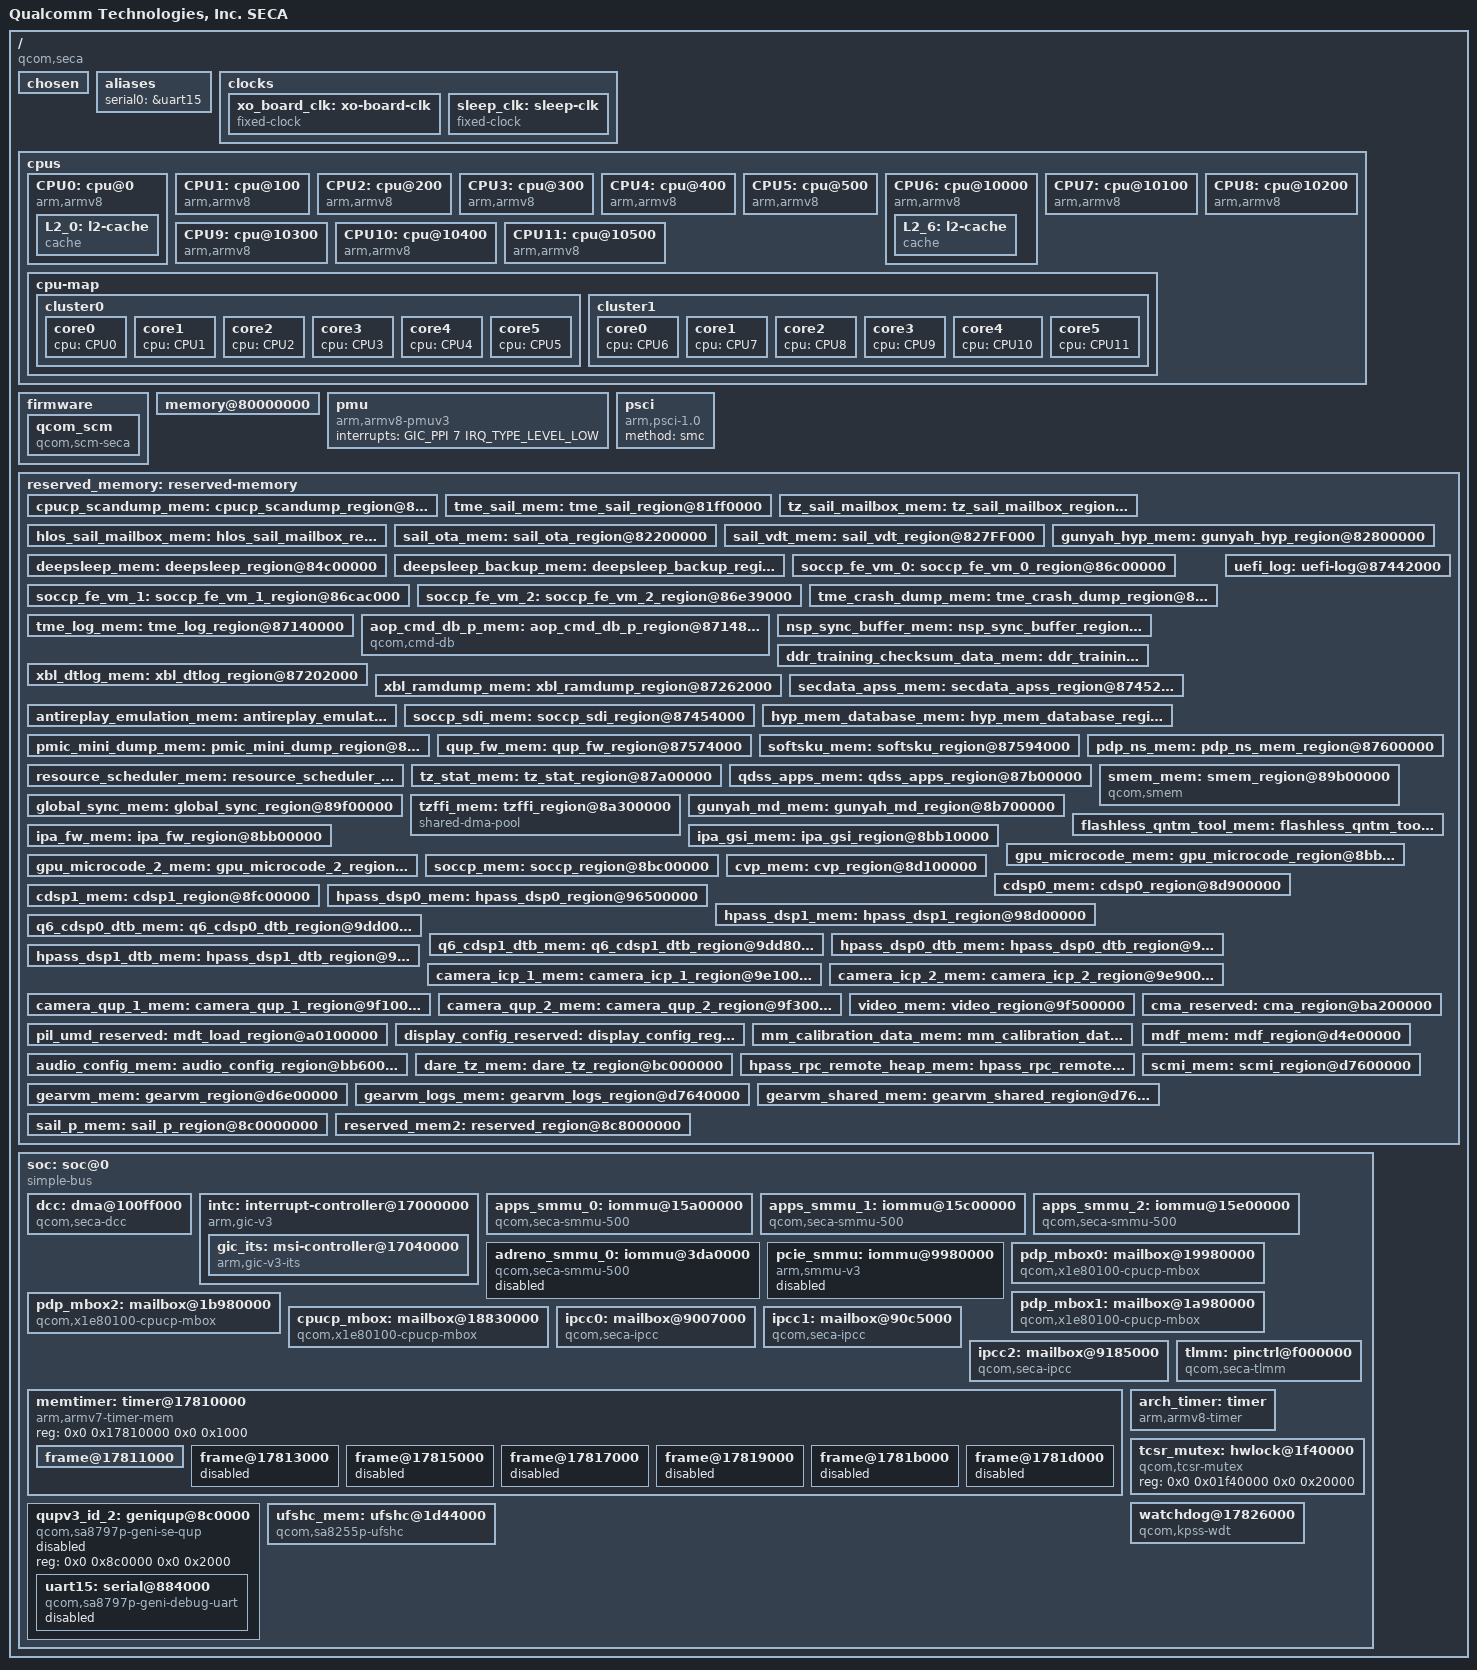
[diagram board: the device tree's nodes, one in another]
// SPDX-License-Identifier: BSD-3-Clause
/*
 * Copyright (c) Qualcomm Technologies, Inc. and/or its subsidiaries.
 */

#include <dt-bindings/interrupt-controller/arm-gic.h>
#include <dt-bindings/gpio/gpio.h>

/ {
	model = "Qualcomm Technologies, Inc. SECA";
	compatible = "qcom,seca";
	qcom,msm-id = <742 0x10000>;

	interrupt-parent = <&intc>;

	#address-cells = <2>;
	#size-cells = <2>;

	chosen { };

	aliases {
		serial0 = &uart15;
	};

	clocks {
		xo_board_clk: xo-board-clk {
			compatible = "fixed-clock";
			#clock-cells = <0>;
		};

		sleep_clk: sleep-clk {
			compatible = "fixed-clock";
			#clock-cells = <0>;
		};
	};

	cpus {
		#address-cells = <2>;
		#size-cells = <0>;

		CPU0: cpu@0 {
			device_type = "cpu";
			compatible = "arm,armv8";
			reg = <0x0 0x0>;
			enable-method = "psci";
			next-level-cache = <&L2_0>;
			L2_0: l2-cache {
				compatible = "cache";
				cache-level = <2>;
				cache-unified;
			};
		};

		CPU1: cpu@100 {
			device_type = "cpu";
			compatible = "arm,armv8";
			reg = <0x0 0x100>;
			enable-method = "psci";
			next-level-cache = <&L2_0>;
		};

		CPU2: cpu@200 {
			device_type = "cpu";
			compatible = "arm,armv8";
			reg = <0x0 0x200>;
			enable-method = "psci";
			next-level-cache = <&L2_0>;
		};

		CPU3: cpu@300 {
			device_type = "cpu";
			compatible = "arm,armv8";
			reg = <0x0 0x300>;
			enable-method = "psci";
			next-level-cache = <&L2_0>;
		};

		CPU4: cpu@400 {
			device_type = "cpu";
			compatible = "arm,armv8";
			reg = <0x0 0x400>;
			enable-method = "psci";
			next-level-cache = <&L2_0>;
		};

		CPU5: cpu@500 {
			device_type = "cpu";
			compatible = "arm,armv8";
			reg = <0x0 0x500>;
			enable-method = "psci";
			next-level-cache = <&L2_0>;
		};

		CPU6: cpu@10000 {
			device_type = "cpu";
			compatible = "arm,armv8";
			reg = <0x0 0x10000>;
			enable-method = "psci";
			next-level-cache = <&L2_6>;
			L2_6: l2-cache {
				compatible = "cache";
				cache-level = <2>;
				cache-unified;
			};
		};

		CPU7: cpu@10100 {
			device_type = "cpu";
			compatible = "arm,armv8";
			reg = <0x0 0x10100>;
			enable-method = "psci";
			next-level-cache = <&L2_6>;
		};

		CPU8: cpu@10200 {
			device_type = "cpu";
			compatible = "arm,armv8";
			reg = <0x0 0x10200>;
			enable-method = "psci";
			next-level-cache = <&L2_6>;
		};

		CPU9: cpu@10300 {
			device_type = "cpu";
			compatible = "arm,armv8";
			reg = <0x0 0x10300>;
			enable-method = "psci";
			next-level-cache = <&L2_6>;
		};

		CPU10: cpu@10400 {
			device_type = "cpu";
			compatible = "arm,armv8";
			reg = <0x0 0x10400>;
			enable-method = "psci";
			next-level-cache = <&L2_6>;
		};

		CPU11: cpu@10500 {
			device_type = "cpu";
			compatible = "arm,armv8";
			reg = <0x0 0x10500>;
			enable-method = "psci";
			next-level-cache = <&L2_6>;
		};

		cpu-map {
			cluster0 {
				core0 {
					cpu = <&CPU0>;
				};

				core1 {
					cpu = <&CPU1>;
				};

				core2 {
					cpu = <&CPU2>;
				};

				core3 {
					cpu = <&CPU3>;
				};

				core4 {
					cpu = <&CPU4>;
				};

				core5 {
					cpu = <&CPU5>;
				};
			};

			cluster1 {
				core0 {
					cpu = <&CPU6>;
				};

				core1 {
					cpu = <&CPU7>;
				};

				core2 {
					cpu = <&CPU8>;
				};

				core3 {
					cpu = <&CPU9>;
				};

				core4 {
					cpu = <&CPU10>;
				};

				core5 {
					cpu = <&CPU11>;
				};
			};
		};
	};

	firmware {
		qcom_scm {
			compatible = "qcom,scm-seca", "qcom,scm";
		};
	};

	memory@80000000 {
		ddr_device_type = <0x08>;
		device_type = "memory";
		reg = <0x0 0x80000000 0x0 0x80000000>;
	};

	pmu {
		compatible = "arm,armv8-pmuv3";
		interrupts = <GIC_PPI 7 IRQ_TYPE_LEVEL_LOW>;
	};

	psci {
		compatible = "arm,psci-1.0";
		method = "smc";
	};

	reserved_memory: reserved-memory {
		#address-cells = <2>;
		#size-cells = <2>;
		ranges;

		cpucp_scandump_mem: cpucp_scandump_region@80000000 {
			no-map;
			reg = <0x0 0x80000000 0x0 0x800000>;
		};

		tme_sail_mem: tme_sail_region@81ff0000 {
			no-map;
			reg = <0x0 0x81ff0000 0x0 0x10000>;
		};

		tz_sail_mailbox_mem: tz_sail_mailbox_region@82000000 {
			no-map;
			reg = <0x0 0x82000000 0x0 0x8000>;
		};

		hlos_sail_mailbox_mem: hlos_sail_mailbox_region@82008000 {
			no-map;
			reg = <0x0 0x82008000 0x0 0x1F8000>;
		};

		sail_ota_mem: sail_ota_region@82200000 {
			no-map;
			reg = <0x0 0x82200000 0x0 0x5FF000>;
		};

		sail_vdt_mem: sail_vdt_region@827FF000 {
			no-map;
			reg = <0x0 0x827FF000 0x0 0x1000>;
		};

		gunyah_hyp_mem: gunyah_hyp_region@82800000 {
			no-map;
			reg = <0x0 0x82800000 0x0 0x2400000>;
		};

		deepsleep_mem: deepsleep_region@84c00000 {
			no-map;
			reg = <0x0 0x84c00000 0x0 0x800000>;
		};

		deepsleep_backup_mem: deepsleep_backup_region@86a00000 {
			no-map;
			reg = <0x0 0x86a00000 0x0 0x200000>;
		};

		soccp_fe_vm_0: soccp_fe_vm_0_region@86c00000 {
			no-map;
			reg = <0x0 0x86c00000 0x0 0xac000>;
		};

		soccp_fe_vm_1: soccp_fe_vm_1_region@86cac000 {
			no-map;
			reg = <0x0 0x86cac000 0x0 0x18d000>;
		};

		soccp_fe_vm_2: soccp_fe_vm_2_region@86e39000 {
			no-map;
			reg = <0x0 0x86e39000 0x0 0x1c7000>;
		};

		tme_crash_dump_mem: tme_crash_dump_region@87000000 {
			no-map;
			reg = <0x0 0x87000000 0x0 0xa0000>;
		};

		tme_log_mem: tme_log_region@87140000 {
			no-map;
			reg = <0x0 0x87140000 0x0 0x4000>;
		};

		aop_cmd_db_p_mem: aop_cmd_db_p_region@87148000 {
			compatible = "qcom,cmd-db";
			no-map;
			reg = <0x0 0x87148000 0x0 0x20000>;
		};

		nsp_sync_buffer_mem: nsp_sync_buffer_region@871ff000 {
			no-map;
			reg = <0x0 0x871ff000 0x0 0x1000>;
		};

		ddr_training_checksum_data_mem: ddr_training_checksum_data_region@87200000 {
			no-map;
			reg = <0x0 0x87200000 0x0 0x2000>;
		};

		xbl_dtlog_mem: xbl_dtlog_region@87202000 {
			no-map;
			reg = <0x0 0x87202000 0x0 0x60000>;
		};

		xbl_ramdump_mem: xbl_ramdump_region@87262000 {
			no-map;
			reg = <0x0 0x87262000 0x0 0x1c0000>;
		};

		uefi_log: uefi-log@87442000 {
			reg = <0x0 0x87442000 0x0 0x10000>;
			no-map;
		};

		secdata_apss_mem: secdata_apss_region@87452000 {
			no-map;
			reg = <0x0 0x87452000 0x0 0x1000>;
		};

		antireplay_emulation_mem: antireplay_emulation_region@87453000 {
			no-map;
			reg = <0x0 0x87453000 0x0 0x1000>;
		};

		soccp_sdi_mem: soccp_sdi_region@87454000 {
			no-map;
			reg = <0x0 0x87454000 0x0 0x40000>;
		};

		hyp_mem_database_mem: hyp_mem_database_region@87494000 {
			no-map;
			reg = <0x0 0x87494000 0x0 0x60000>;
		};

		pmic_mini_dump_mem: pmic_mini_dump_region@874f4000 {
			no-map;
			reg = <0x0 0x874f4000 0x0 0x80000>;
		};

		qup_fw_mem: qup_fw_region@87574000 {
			no-map;
			reg = <0x0 0x87574000 0x0 0x20000>;
		};

		softsku_mem: softsku_region@87594000 {
			no-map;
			reg = <0x0 0x87594000 0x0 0x9000>;
		};

		resource_scheduler_mem: resource_scheduler_region@8759d000 {
			no-map;
			reg = <0x0 0x8759d000 0x0 0x20000>;
		};

		pdp_ns_mem: pdp_ns_mem_region@87600000 {
			no-map;
			reg = <0x0 0x87600000 0x0 0x200000>;
		};

		tz_stat_mem: tz_stat_region@87a00000 {
			no-map;
			reg = <0x0 0x87a00000 0x0 0x100000>;
		};

		qdss_apps_mem: qdss_apps_region@87b00000 {
			no-map;
			reg = <0x0 0x87b00000 0x0 0x2000000>;
		};

		smem_mem: smem_region@89b00000 {
			compatible = "qcom,smem";
			no-map;
			reg = <0x0 0x89b00000 0x0 0x400000>;
			hwlocks = <&tcsr_mutex 3>;
		};

		global_sync_mem: global_sync_region@89f00000 {
			no-map;
			reg = <0x0 0x89f00000 0x0 0x400000>;
		};

		tzffi_mem: tzffi_region@8a300000 {
			compatible = "shared-dma-pool";
			reg = <0x0 0x8a300000 0x0 0x1400000>;
			no-map;
		};

		gunyah_md_mem: gunyah_md_region@8b700000 {
			no-map;
			reg = <0x0 0x8b700000 0x0 0x80000>;
		};

		flashless_qntm_tool_mem: flashless_qntm_tool_region@8b780000 {
			no-map;
			reg = <0x0 0x8b780000 0x0 0x182000>;
		};

		ipa_fw_mem: ipa_fw_region@8bb00000 {
			no-map;
			reg = <0x0 0x8bb00000 0x0 0x10000>;
		};

		ipa_gsi_mem: ipa_gsi_region@8bb10000 {
			no-map;
			reg = <0x0 0x8bb10000 0x0 0xa000>;
		};

		gpu_microcode_mem: gpu_microcode_region@8bb1a000 {
			no-map;
			reg = <0x0 0x8bb1a000 0x0 0x2000>;
		};

		gpu_microcode_2_mem: gpu_microcode_2_region@8bb1c000 {
			no-map;
			reg = <0x0 0x8bb1c000 0x0 0x2000>;
		};

		soccp_mem: soccp_region@8bc00000 {
			no-map;
			reg = <0x0 0x8bc00000 0x0 0x300000>;
		};

		cvp_mem: cvp_region@8d100000 {
			no-map;
			reg = <0x0 0x8d100000 0x0 0x800000>;
		};

		cdsp0_mem: cdsp0_region@8d900000 {
			no-map;
			reg = <0x0 0x8d900000 0x0 0x2300000>;
		};

		cdsp1_mem: cdsp1_region@8fc00000 {
			no-map;
			reg = <0x0 0x8fc00000 0x0 0x2300000>;
		};

		hpass_dsp0_mem: hpass_dsp0_region@96500000 {
			no-map;
			reg = <0x0 0x96500000 0x0 0x2800000>;
		};

		hpass_dsp1_mem: hpass_dsp1_region@98d00000 {
			no-map;
			reg = <0x0 0x98d00000 0x0 0x2800000>;
		};

		q6_cdsp0_dtb_mem: q6_cdsp0_dtb_region@9dd00000 {
			no-map;
			reg = <0x0 0x9dd00000 0x0 0x80000>;
		};

		q6_cdsp1_dtb_mem: q6_cdsp1_dtb_region@9dd80000 {
			no-map;
			reg = <0x0 0x9dd80000 0x0 0x80000>;
		};

		hpass_dsp0_dtb_mem: hpass_dsp0_dtb_region@9df00000 {
			no-map;
			reg = <0x0 0x9df00000 0x0 0x80000>;
		};

		hpass_dsp1_dtb_mem: hpass_dsp1_dtb_region@9df80000 {
			no-map;
			reg = <0x0 0x9df80000 0x0 0x80000>;
		};

		camera_icp_1_mem: camera_icp_1_region@9e100000 {
			no-map;
			reg = <0x0 0x9e100000 0x0 0x800000>;
		};

		camera_icp_2_mem: camera_icp_2_region@9e900000 {
			no-map;
			reg = <0x0 0x9e900000 0x0 0x800000>;
		};

		camera_qup_1_mem: camera_qup_1_region@9f100000 {
			no-map;
			reg = <0x0 0x9f100000 0x0 0x200000>;
		};

		camera_qup_2_mem: camera_qup_2_region@9f300000 {
			no-map;
			reg = <0x0 0x9f300000 0x0 0x200000>;
		};

		video_mem: video_region@9f500000 {
			no-map;
			reg = <0x0 0x9f500000 0x0 0xc00000>;
		};

		pil_umd_reserved: mdt_load_region@a0100000 {
			no-map;
			reg = <0x0 0xa0100000 0x0 0x100000>;
		};

		cma_reserved: cma_region@ba200000 {
			no-map;
			reg = <0x0 0xba200000 0x0 0x200000>;
		};

		display_config_reserved: display_config_region@ba400000 {
			no-map;
			reg = <0x0 0xba400000 0x0 0xa00000>;
		};

		mm_calibration_data_mem: mm_calibration_data_region@bae00000 {
			no-map;
			reg = <0x0 0xbae00000 0x0 0x800000>;
		};

		audio_config_mem: audio_config_region@bb600000 {
			no-map;
			reg = <0x0 0xbb600000 0x0 0xa00000>;
		};

		dare_tz_mem: dare_tz_region@bc000000 {
			no-map;
			reg = <0x0 0xbc000000 0x0 0xa300000>;
		};

		hpass_rpc_remote_heap_mem: hpass_rpc_remote_heap_region@d4600000 {
			no-map;
			reg = <0x0 0xd4600000 0x0 0x800000>;
		};

		mdf_mem: mdf_region@d4e00000 {
			no-map;
			reg = <0x0 0xd4e00000 0x0 0x2000000>;
		};

		gearvm_mem: gearvm_region@d6e00000 {
			no-map;
			reg = <0x0 0xd6e00000 0x0 0x800000>;
		};

		scmi_mem: scmi_region@d7600000 {
			no-map;
			reg = <0x0 0xd7600000 0x0 0x40000>;
		};

		gearvm_logs_mem: gearvm_logs_region@d7640000 {
			no-map;
			reg = <0x0 0xd7640000 0x0 0x10000>;
		};

		gearvm_shared_mem: gearvm_shared_region@d7650000 {
			no-map;
			reg = <0x0 0xd7650000 0x0 0x1b0000>;
		};

		sail_p_mem: sail_p_region@8c0000000 {
			no-map;
			reg = <0x8 0xc0000000 0x0 0x8000000>;
		};

		reserved_mem2: reserved_region@8c8000000 {
			no-map;
			reg = <0x8 0xc8000000 0x0 0x18000000>;
		};
	};

	soc: soc@0 {
		compatible = "simple-bus";
		#address-cells = <2>;
		#size-cells = <2>;
		ranges = <0 0 0 0 0x10 0>;

		dcc: dma@100ff000 {
			compatible = "qcom,seca-dcc", "qcom,dcc-v3";
			reg = <0x0 0x100ff000 0x0 0x1000>,
				<0x0 0x10080000 0x0 0x6000>;
			qcom,dcc-offset = <0>;
		};

		intc: interrupt-controller@17000000 {
			compatible = "arm,gic-v3";
			#address-cells = <2>;
			#size-cells = <2>;
			reg = <0x0 0x17000000 0x0 0x10000>,     /* GICD */
			      <0x0 0x17080000 0x0 0x480000>;    /* GICR * 18 */
			interrupt-controller;
			#interrupt-cells = <3>;
			interrupts = <GIC_PPI 9 IRQ_TYPE_LEVEL_HIGH>;
			#redistributor-regions = <1>;
			redistributor-stride = <0x0 0x40000>;
			ranges;

			gic_its: msi-controller@17040000 {
				compatible = "arm,gic-v3-its";
				reg = <0x0 0x17040000 0x0 0x40000>;
				msi-controller;
				#msi-cells = <1>;
			};
		};

		apps_smmu_0: iommu@15a00000 {
			compatible = "qcom,seca-smmu-500", "qcom,smmu-500", "arm,mmu-500";
			reg = <0x0 0x15A00000 0x0 0x100000>;
			#iommu-cells = <2>;
			#global-interrupts = <1>;
			dma-coherent;
			interrupts =	<GIC_SPI 886 IRQ_TYPE_LEVEL_HIGH>,
					<GIC_ESPI 32 IRQ_TYPE_LEVEL_HIGH>,
					<GIC_ESPI 33 IRQ_TYPE_LEVEL_HIGH>,
					<GIC_ESPI 34 IRQ_TYPE_LEVEL_HIGH>,
					<GIC_ESPI 35 IRQ_TYPE_LEVEL_HIGH>,
					<GIC_ESPI 36 IRQ_TYPE_LEVEL_HIGH>,
					<GIC_ESPI 37 IRQ_TYPE_LEVEL_HIGH>,
					<GIC_ESPI 38 IRQ_TYPE_LEVEL_HIGH>,
					<GIC_ESPI 39 IRQ_TYPE_LEVEL_HIGH>,
					<GIC_ESPI 40 IRQ_TYPE_LEVEL_HIGH>,
					<GIC_ESPI 41 IRQ_TYPE_LEVEL_HIGH>,
					<GIC_ESPI 42 IRQ_TYPE_LEVEL_HIGH>,
					<GIC_ESPI 43 IRQ_TYPE_LEVEL_HIGH>,
					<GIC_ESPI 44 IRQ_TYPE_LEVEL_HIGH>,
					<GIC_ESPI 45 IRQ_TYPE_LEVEL_HIGH>,
					<GIC_ESPI 46 IRQ_TYPE_LEVEL_HIGH>,
					<GIC_ESPI 47 IRQ_TYPE_LEVEL_HIGH>,
					<GIC_ESPI 48 IRQ_TYPE_LEVEL_HIGH>,
					<GIC_ESPI 49 IRQ_TYPE_LEVEL_HIGH>,
					<GIC_ESPI 50 IRQ_TYPE_LEVEL_HIGH>,
					<GIC_ESPI 51 IRQ_TYPE_LEVEL_HIGH>,
					<GIC_ESPI 52 IRQ_TYPE_LEVEL_HIGH>,
					<GIC_ESPI 53 IRQ_TYPE_LEVEL_HIGH>,
					<GIC_ESPI 54 IRQ_TYPE_LEVEL_HIGH>,
					<GIC_ESPI 55 IRQ_TYPE_LEVEL_HIGH>,
					<GIC_ESPI 56 IRQ_TYPE_LEVEL_HIGH>,
					<GIC_ESPI 57 IRQ_TYPE_LEVEL_HIGH>,
					<GIC_ESPI 58 IRQ_TYPE_LEVEL_HIGH>,
					<GIC_ESPI 59 IRQ_TYPE_LEVEL_HIGH>,
					<GIC_ESPI 60 IRQ_TYPE_LEVEL_HIGH>,
					<GIC_ESPI 61 IRQ_TYPE_LEVEL_HIGH>,
					<GIC_ESPI 62 IRQ_TYPE_LEVEL_HIGH>,
					<GIC_ESPI 63 IRQ_TYPE_LEVEL_HIGH>,
					<GIC_ESPI 64 IRQ_TYPE_LEVEL_HIGH>,
					<GIC_ESPI 65 IRQ_TYPE_LEVEL_HIGH>,
					<GIC_ESPI 66 IRQ_TYPE_LEVEL_HIGH>,
					<GIC_ESPI 67 IRQ_TYPE_LEVEL_HIGH>,
					<GIC_ESPI 68 IRQ_TYPE_LEVEL_HIGH>,
					<GIC_ESPI 69 IRQ_TYPE_LEVEL_HIGH>,
					<GIC_ESPI 70 IRQ_TYPE_LEVEL_HIGH>,
					<GIC_ESPI 71 IRQ_TYPE_LEVEL_HIGH>,
					<GIC_ESPI 72 IRQ_TYPE_LEVEL_HIGH>,
					<GIC_ESPI 73 IRQ_TYPE_LEVEL_HIGH>,
					<GIC_ESPI 74 IRQ_TYPE_LEVEL_HIGH>,
					<GIC_ESPI 75 IRQ_TYPE_LEVEL_HIGH>,
					<GIC_ESPI 76 IRQ_TYPE_LEVEL_HIGH>,
					<GIC_ESPI 77 IRQ_TYPE_LEVEL_HIGH>,
					<GIC_ESPI 78 IRQ_TYPE_LEVEL_HIGH>,
					<GIC_ESPI 79 IRQ_TYPE_LEVEL_HIGH>,
					<GIC_ESPI 80 IRQ_TYPE_LEVEL_HIGH>,
					<GIC_ESPI 81 IRQ_TYPE_LEVEL_HIGH>,
					<GIC_ESPI 82 IRQ_TYPE_LEVEL_HIGH>,
					<GIC_ESPI 83 IRQ_TYPE_LEVEL_HIGH>,
					<GIC_ESPI 84 IRQ_TYPE_LEVEL_HIGH>,
					<GIC_ESPI 85 IRQ_TYPE_LEVEL_HIGH>,
					<GIC_ESPI 86 IRQ_TYPE_LEVEL_HIGH>,
					<GIC_ESPI 87 IRQ_TYPE_LEVEL_HIGH>,
					<GIC_ESPI 88 IRQ_TYPE_LEVEL_HIGH>,
					<GIC_ESPI 89 IRQ_TYPE_LEVEL_HIGH>,
					<GIC_ESPI 90 IRQ_TYPE_LEVEL_HIGH>,
					<GIC_ESPI 91 IRQ_TYPE_LEVEL_HIGH>,
					<GIC_ESPI 92 IRQ_TYPE_LEVEL_HIGH>,
					<GIC_ESPI 93 IRQ_TYPE_LEVEL_HIGH>,
					<GIC_ESPI 94 IRQ_TYPE_LEVEL_HIGH>,
					<GIC_ESPI 95 IRQ_TYPE_LEVEL_HIGH>,
					<GIC_ESPI 96 IRQ_TYPE_LEVEL_HIGH>,
					<GIC_ESPI 97 IRQ_TYPE_LEVEL_HIGH>,
					<GIC_ESPI 98 IRQ_TYPE_LEVEL_HIGH>,
					<GIC_ESPI 99 IRQ_TYPE_LEVEL_HIGH>,
					<GIC_ESPI 100 IRQ_TYPE_LEVEL_HIGH>,
					<GIC_ESPI 101 IRQ_TYPE_LEVEL_HIGH>,
					<GIC_ESPI 102 IRQ_TYPE_LEVEL_HIGH>,
					<GIC_ESPI 103 IRQ_TYPE_LEVEL_HIGH>,
					<GIC_ESPI 104 IRQ_TYPE_LEVEL_HIGH>,
					<GIC_ESPI 105 IRQ_TYPE_LEVEL_HIGH>,
					<GIC_ESPI 106 IRQ_TYPE_LEVEL_HIGH>,
					<GIC_ESPI 107 IRQ_TYPE_LEVEL_HIGH>,
					<GIC_ESPI 108 IRQ_TYPE_LEVEL_HIGH>,
					<GIC_ESPI 109 IRQ_TYPE_LEVEL_HIGH>,
					<GIC_ESPI 110 IRQ_TYPE_LEVEL_HIGH>,
					<GIC_ESPI 111 IRQ_TYPE_LEVEL_HIGH>,
					<GIC_ESPI 112 IRQ_TYPE_LEVEL_HIGH>,
					<GIC_ESPI 113 IRQ_TYPE_LEVEL_HIGH>,
					<GIC_ESPI 114 IRQ_TYPE_LEVEL_HIGH>,
					<GIC_ESPI 115 IRQ_TYPE_LEVEL_HIGH>,
					<GIC_ESPI 116 IRQ_TYPE_LEVEL_HIGH>,
					<GIC_ESPI 117 IRQ_TYPE_LEVEL_HIGH>,
					<GIC_ESPI 118 IRQ_TYPE_LEVEL_HIGH>,
					<GIC_ESPI 119 IRQ_TYPE_LEVEL_HIGH>,
					<GIC_ESPI 120 IRQ_TYPE_LEVEL_HIGH>,
					<GIC_ESPI 121 IRQ_TYPE_LEVEL_HIGH>,
					<GIC_ESPI 122 IRQ_TYPE_LEVEL_HIGH>,
					<GIC_ESPI 123 IRQ_TYPE_LEVEL_HIGH>,
					<GIC_ESPI 124 IRQ_TYPE_LEVEL_HIGH>,
					<GIC_ESPI 125 IRQ_TYPE_LEVEL_HIGH>,
					<GIC_ESPI 126 IRQ_TYPE_LEVEL_HIGH>,
					<GIC_ESPI 127 IRQ_TYPE_LEVEL_HIGH>;
		};

		apps_smmu_1: iommu@15c00000 {
			compatible = "qcom,seca-smmu-500", "qcom,smmu-500", "arm,mmu-500";
			reg = <0x0 0x15C00000 0x0 0x100000>;
			#iommu-cells = <2>;
			#global-interrupts = <1>;
			dma-coherent;
			interrupts =	<GIC_SPI 882 IRQ_TYPE_LEVEL_HIGH>,
					<GIC_ESPI 128 IRQ_TYPE_LEVEL_HIGH>,
					<GIC_ESPI 129 IRQ_TYPE_LEVEL_HIGH>,
					<GIC_ESPI 130 IRQ_TYPE_LEVEL_HIGH>,
					<GIC_ESPI 131 IRQ_TYPE_LEVEL_HIGH>,
					<GIC_ESPI 132 IRQ_TYPE_LEVEL_HIGH>,
					<GIC_ESPI 133 IRQ_TYPE_LEVEL_HIGH>,
					<GIC_ESPI 134 IRQ_TYPE_LEVEL_HIGH>,
					<GIC_ESPI 135 IRQ_TYPE_LEVEL_HIGH>,
					<GIC_ESPI 136 IRQ_TYPE_LEVEL_HIGH>,
					<GIC_ESPI 137 IRQ_TYPE_LEVEL_HIGH>,
					<GIC_ESPI 138 IRQ_TYPE_LEVEL_HIGH>,
					<GIC_ESPI 139 IRQ_TYPE_LEVEL_HIGH>,
					<GIC_ESPI 140 IRQ_TYPE_LEVEL_HIGH>,
					<GIC_ESPI 141 IRQ_TYPE_LEVEL_HIGH>,
					<GIC_ESPI 142 IRQ_TYPE_LEVEL_HIGH>,
					<GIC_ESPI 143 IRQ_TYPE_LEVEL_HIGH>,
					<GIC_ESPI 144 IRQ_TYPE_LEVEL_HIGH>,
					<GIC_ESPI 145 IRQ_TYPE_LEVEL_HIGH>,
					<GIC_ESPI 146 IRQ_TYPE_LEVEL_HIGH>,
					<GIC_ESPI 147 IRQ_TYPE_LEVEL_HIGH>,
					<GIC_ESPI 148 IRQ_TYPE_LEVEL_HIGH>,
					<GIC_ESPI 149 IRQ_TYPE_LEVEL_HIGH>,
					<GIC_ESPI 150 IRQ_TYPE_LEVEL_HIGH>,
					<GIC_ESPI 151 IRQ_TYPE_LEVEL_HIGH>,
					<GIC_ESPI 152 IRQ_TYPE_LEVEL_HIGH>,
					<GIC_ESPI 153 IRQ_TYPE_LEVEL_HIGH>,
					<GIC_ESPI 154 IRQ_TYPE_LEVEL_HIGH>,
					<GIC_ESPI 155 IRQ_TYPE_LEVEL_HIGH>,
					<GIC_ESPI 156 IRQ_TYPE_LEVEL_HIGH>,
					<GIC_ESPI 157 IRQ_TYPE_LEVEL_HIGH>,
					<GIC_ESPI 158 IRQ_TYPE_LEVEL_HIGH>,
					<GIC_ESPI 159 IRQ_TYPE_LEVEL_HIGH>,
					<GIC_ESPI 160 IRQ_TYPE_LEVEL_HIGH>,
					<GIC_ESPI 161 IRQ_TYPE_LEVEL_HIGH>,
					<GIC_ESPI 162 IRQ_TYPE_LEVEL_HIGH>,
					<GIC_ESPI 163 IRQ_TYPE_LEVEL_HIGH>,
					<GIC_ESPI 164 IRQ_TYPE_LEVEL_HIGH>,
					<GIC_ESPI 165 IRQ_TYPE_LEVEL_HIGH>,
					<GIC_ESPI 166 IRQ_TYPE_LEVEL_HIGH>,
					<GIC_ESPI 167 IRQ_TYPE_LEVEL_HIGH>,
					<GIC_ESPI 168 IRQ_TYPE_LEVEL_HIGH>,
					<GIC_ESPI 169 IRQ_TYPE_LEVEL_HIGH>,
					<GIC_ESPI 170 IRQ_TYPE_LEVEL_HIGH>,
					<GIC_ESPI 171 IRQ_TYPE_LEVEL_HIGH>,
					<GIC_ESPI 172 IRQ_TYPE_LEVEL_HIGH>,
					<GIC_ESPI 173 IRQ_TYPE_LEVEL_HIGH>,
					<GIC_ESPI 174 IRQ_TYPE_LEVEL_HIGH>,
					<GIC_ESPI 175 IRQ_TYPE_LEVEL_HIGH>,
					<GIC_ESPI 176 IRQ_TYPE_LEVEL_HIGH>,
					<GIC_ESPI 177 IRQ_TYPE_LEVEL_HIGH>,
					<GIC_ESPI 178 IRQ_TYPE_LEVEL_HIGH>,
					<GIC_ESPI 179 IRQ_TYPE_LEVEL_HIGH>,
					<GIC_ESPI 180 IRQ_TYPE_LEVEL_HIGH>,
					<GIC_ESPI 181 IRQ_TYPE_LEVEL_HIGH>,
					<GIC_ESPI 182 IRQ_TYPE_LEVEL_HIGH>,
					<GIC_ESPI 183 IRQ_TYPE_LEVEL_HIGH>,
					<GIC_ESPI 184 IRQ_TYPE_LEVEL_HIGH>,
					<GIC_ESPI 185 IRQ_TYPE_LEVEL_HIGH>,
					<GIC_ESPI 186 IRQ_TYPE_LEVEL_HIGH>,
					<GIC_ESPI 187 IRQ_TYPE_LEVEL_HIGH>,
					<GIC_ESPI 188 IRQ_TYPE_LEVEL_HIGH>,
					<GIC_ESPI 189 IRQ_TYPE_LEVEL_HIGH>,
					<GIC_ESPI 190 IRQ_TYPE_LEVEL_HIGH>,
					<GIC_ESPI 191 IRQ_TYPE_LEVEL_HIGH>,
					<GIC_ESPI 192 IRQ_TYPE_LEVEL_HIGH>,
					<GIC_ESPI 193 IRQ_TYPE_LEVEL_HIGH>,
					<GIC_ESPI 194 IRQ_TYPE_LEVEL_HIGH>,
					<GIC_ESPI 195 IRQ_TYPE_LEVEL_HIGH>,
					<GIC_ESPI 196 IRQ_TYPE_LEVEL_HIGH>,
					<GIC_ESPI 197 IRQ_TYPE_LEVEL_HIGH>,
					<GIC_ESPI 198 IRQ_TYPE_LEVEL_HIGH>,
					<GIC_ESPI 199 IRQ_TYPE_LEVEL_HIGH>,
					<GIC_ESPI 200 IRQ_TYPE_LEVEL_HIGH>,
					<GIC_ESPI 201 IRQ_TYPE_LEVEL_HIGH>,
					<GIC_ESPI 202 IRQ_TYPE_LEVEL_HIGH>,
					<GIC_ESPI 203 IRQ_TYPE_LEVEL_HIGH>,
					<GIC_ESPI 204 IRQ_TYPE_LEVEL_HIGH>,
					<GIC_ESPI 205 IRQ_TYPE_LEVEL_HIGH>,
					<GIC_ESPI 206 IRQ_TYPE_LEVEL_HIGH>,
					<GIC_ESPI 207 IRQ_TYPE_LEVEL_HIGH>,
					<GIC_ESPI 208 IRQ_TYPE_LEVEL_HIGH>,
					<GIC_ESPI 209 IRQ_TYPE_LEVEL_HIGH>,
					<GIC_ESPI 210 IRQ_TYPE_LEVEL_HIGH>,
					<GIC_ESPI 211 IRQ_TYPE_LEVEL_HIGH>,
					<GIC_ESPI 212 IRQ_TYPE_LEVEL_HIGH>,
					<GIC_ESPI 213 IRQ_TYPE_LEVEL_HIGH>,
					<GIC_ESPI 214 IRQ_TYPE_LEVEL_HIGH>,
					<GIC_ESPI 215 IRQ_TYPE_LEVEL_HIGH>,
					<GIC_ESPI 216 IRQ_TYPE_LEVEL_HIGH>,
					<GIC_ESPI 217 IRQ_TYPE_LEVEL_HIGH>,
					<GIC_ESPI 218 IRQ_TYPE_LEVEL_HIGH>,
					<GIC_ESPI 219 IRQ_TYPE_LEVEL_HIGH>,
					<GIC_ESPI 220 IRQ_TYPE_LEVEL_HIGH>,
					<GIC_ESPI 221 IRQ_TYPE_LEVEL_HIGH>,
					<GIC_ESPI 222 IRQ_TYPE_LEVEL_HIGH>,
					<GIC_ESPI 223 IRQ_TYPE_LEVEL_HIGH>;
		};

		apps_smmu_2: iommu@15e00000 {
			compatible = "qcom,seca-smmu-500", "qcom,smmu-500", "arm,mmu-500";
			reg = <0x0 0x15E00000 0x0 0x100000>;
			#iommu-cells = <2>;
			#global-interrupts = <1>;
			dma-coherent;
			interrupts =	<GIC_SPI 877 IRQ_TYPE_LEVEL_HIGH>,
					<GIC_ESPI 224 IRQ_TYPE_LEVEL_HIGH>,
					<GIC_ESPI 225 IRQ_TYPE_LEVEL_HIGH>,
					<GIC_ESPI 226 IRQ_TYPE_LEVEL_HIGH>,
					<GIC_ESPI 227 IRQ_TYPE_LEVEL_HIGH>,
					<GIC_ESPI 228 IRQ_TYPE_LEVEL_HIGH>,
					<GIC_ESPI 229 IRQ_TYPE_LEVEL_HIGH>,
					<GIC_ESPI 230 IRQ_TYPE_LEVEL_HIGH>,
					<GIC_ESPI 231 IRQ_TYPE_LEVEL_HIGH>,
					<GIC_ESPI 232 IRQ_TYPE_LEVEL_HIGH>,
					<GIC_ESPI 233 IRQ_TYPE_LEVEL_HIGH>,
					<GIC_ESPI 234 IRQ_TYPE_LEVEL_HIGH>,
					<GIC_ESPI 235 IRQ_TYPE_LEVEL_HIGH>,
					<GIC_ESPI 236 IRQ_TYPE_LEVEL_HIGH>,
					<GIC_ESPI 237 IRQ_TYPE_LEVEL_HIGH>,
					<GIC_ESPI 238 IRQ_TYPE_LEVEL_HIGH>,
					<GIC_ESPI 239 IRQ_TYPE_LEVEL_HIGH>,
					<GIC_ESPI 240 IRQ_TYPE_LEVEL_HIGH>,
					<GIC_ESPI 241 IRQ_TYPE_LEVEL_HIGH>,
					<GIC_ESPI 242 IRQ_TYPE_LEVEL_HIGH>,
					<GIC_ESPI 243 IRQ_TYPE_LEVEL_HIGH>,
					<GIC_ESPI 244 IRQ_TYPE_LEVEL_HIGH>,
					<GIC_ESPI 245 IRQ_TYPE_LEVEL_HIGH>,
					<GIC_ESPI 246 IRQ_TYPE_LEVEL_HIGH>,
					<GIC_ESPI 247 IRQ_TYPE_LEVEL_HIGH>,
					<GIC_ESPI 248 IRQ_TYPE_LEVEL_HIGH>,
					<GIC_ESPI 249 IRQ_TYPE_LEVEL_HIGH>,
					<GIC_ESPI 250 IRQ_TYPE_LEVEL_HIGH>,
					<GIC_ESPI 251 IRQ_TYPE_LEVEL_HIGH>,
					<GIC_ESPI 252 IRQ_TYPE_LEVEL_HIGH>,
					<GIC_ESPI 253 IRQ_TYPE_LEVEL_HIGH>,
					<GIC_ESPI 254 IRQ_TYPE_LEVEL_HIGH>,
					<GIC_ESPI 255 IRQ_TYPE_LEVEL_HIGH>,
					<GIC_ESPI 256 IRQ_TYPE_LEVEL_HIGH>,
					<GIC_ESPI 257 IRQ_TYPE_LEVEL_HIGH>,
					<GIC_ESPI 258 IRQ_TYPE_LEVEL_HIGH>,
					<GIC_ESPI 259 IRQ_TYPE_LEVEL_HIGH>,
					<GIC_ESPI 260 IRQ_TYPE_LEVEL_HIGH>,
					<GIC_ESPI 261 IRQ_TYPE_LEVEL_HIGH>,
					<GIC_ESPI 262 IRQ_TYPE_LEVEL_HIGH>,
					<GIC_ESPI 263 IRQ_TYPE_LEVEL_HIGH>,
					<GIC_ESPI 264 IRQ_TYPE_LEVEL_HIGH>,
					<GIC_ESPI 265 IRQ_TYPE_LEVEL_HIGH>,
					<GIC_ESPI 266 IRQ_TYPE_LEVEL_HIGH>,
					<GIC_ESPI 267 IRQ_TYPE_LEVEL_HIGH>,
					<GIC_ESPI 268 IRQ_TYPE_LEVEL_HIGH>,
					<GIC_ESPI 269 IRQ_TYPE_LEVEL_HIGH>,
					<GIC_ESPI 270 IRQ_TYPE_LEVEL_HIGH>,
					<GIC_ESPI 271 IRQ_TYPE_LEVEL_HIGH>,
					<GIC_ESPI 272 IRQ_TYPE_LEVEL_HIGH>,
					<GIC_ESPI 273 IRQ_TYPE_LEVEL_HIGH>,
					<GIC_ESPI 274 IRQ_TYPE_LEVEL_HIGH>,
					<GIC_ESPI 275 IRQ_TYPE_LEVEL_HIGH>,
					<GIC_ESPI 276 IRQ_TYPE_LEVEL_HIGH>,
					<GIC_ESPI 277 IRQ_TYPE_LEVEL_HIGH>,
					<GIC_ESPI 278 IRQ_TYPE_LEVEL_HIGH>,
					<GIC_ESPI 279 IRQ_TYPE_LEVEL_HIGH>,
					<GIC_ESPI 280 IRQ_TYPE_LEVEL_HIGH>,
					<GIC_ESPI 281 IRQ_TYPE_LEVEL_HIGH>,
					<GIC_ESPI 282 IRQ_TYPE_LEVEL_HIGH>,
					<GIC_ESPI 283 IRQ_TYPE_LEVEL_HIGH>,
					<GIC_ESPI 284 IRQ_TYPE_LEVEL_HIGH>,
					<GIC_ESPI 285 IRQ_TYPE_LEVEL_HIGH>,
					<GIC_ESPI 286 IRQ_TYPE_LEVEL_HIGH>,
					<GIC_ESPI 287 IRQ_TYPE_LEVEL_HIGH>,
					<GIC_ESPI 288 IRQ_TYPE_LEVEL_HIGH>,
					<GIC_ESPI 289 IRQ_TYPE_LEVEL_HIGH>,
					<GIC_ESPI 290 IRQ_TYPE_LEVEL_HIGH>,
					<GIC_ESPI 291 IRQ_TYPE_LEVEL_HIGH>,
					<GIC_ESPI 292 IRQ_TYPE_LEVEL_HIGH>,
					<GIC_ESPI 293 IRQ_TYPE_LEVEL_HIGH>,
					<GIC_ESPI 294 IRQ_TYPE_LEVEL_HIGH>,
					<GIC_ESPI 295 IRQ_TYPE_LEVEL_HIGH>,
					<GIC_ESPI 296 IRQ_TYPE_LEVEL_HIGH>,
					<GIC_ESPI 297 IRQ_TYPE_LEVEL_HIGH>,
					<GIC_ESPI 298 IRQ_TYPE_LEVEL_HIGH>,
					<GIC_ESPI 299 IRQ_TYPE_LEVEL_HIGH>,
					<GIC_ESPI 300 IRQ_TYPE_LEVEL_HIGH>,
					<GIC_ESPI 301 IRQ_TYPE_LEVEL_HIGH>,
					<GIC_ESPI 302 IRQ_TYPE_LEVEL_HIGH>,
					<GIC_ESPI 303 IRQ_TYPE_LEVEL_HIGH>,
					<GIC_ESPI 304 IRQ_TYPE_LEVEL_HIGH>,
					<GIC_ESPI 305 IRQ_TYPE_LEVEL_HIGH>,
					<GIC_ESPI 306 IRQ_TYPE_LEVEL_HIGH>,
					<GIC_ESPI 307 IRQ_TYPE_LEVEL_HIGH>,
					<GIC_ESPI 308 IRQ_TYPE_LEVEL_HIGH>,
					<GIC_ESPI 309 IRQ_TYPE_LEVEL_HIGH>,
					<GIC_ESPI 310 IRQ_TYPE_LEVEL_HIGH>,
					<GIC_ESPI 311 IRQ_TYPE_LEVEL_HIGH>,
					<GIC_ESPI 312 IRQ_TYPE_LEVEL_HIGH>,
					<GIC_ESPI 313 IRQ_TYPE_LEVEL_HIGH>,
					<GIC_ESPI 314 IRQ_TYPE_LEVEL_HIGH>,
					<GIC_ESPI 315 IRQ_TYPE_LEVEL_HIGH>,
					<GIC_ESPI 316 IRQ_TYPE_LEVEL_HIGH>,
					<GIC_ESPI 317 IRQ_TYPE_LEVEL_HIGH>,
					<GIC_ESPI 318 IRQ_TYPE_LEVEL_HIGH>,
					<GIC_ESPI 319 IRQ_TYPE_LEVEL_HIGH>;
		};

		adreno_smmu_0: iommu@3da0000 {
			compatible = "qcom,seca-smmu-500", "qcom,adreno-smmu",
					"qcom,smmu-500", "arm,mmu-500";
			reg = <0x0 0x03da0000 0x0 0x40000>;
			#iommu-cells = <2>;
			#global-interrupts = <1>;
			dma-coherent;
			interrupts = <GIC_SPI 673 IRQ_TYPE_LEVEL_HIGH>,
				<GIC_SPI 678 IRQ_TYPE_LEVEL_HIGH>,
				<GIC_SPI 679 IRQ_TYPE_LEVEL_HIGH>,
				<GIC_SPI 680 IRQ_TYPE_LEVEL_HIGH>,
				<GIC_SPI 681 IRQ_TYPE_LEVEL_HIGH>,
				<GIC_SPI 682 IRQ_TYPE_LEVEL_HIGH>,
				<GIC_SPI 683 IRQ_TYPE_LEVEL_HIGH>,
				<GIC_SPI 684 IRQ_TYPE_LEVEL_HIGH>,
				<GIC_SPI 685 IRQ_TYPE_LEVEL_HIGH>,
				<GIC_SPI 686 IRQ_TYPE_LEVEL_HIGH>,
				<GIC_SPI 687 IRQ_TYPE_LEVEL_HIGH>,
				<GIC_SPI 688 IRQ_TYPE_LEVEL_HIGH>,
				<GIC_SPI 422 IRQ_TYPE_LEVEL_HIGH>,
				<GIC_SPI 476 IRQ_TYPE_LEVEL_HIGH>,
				<GIC_SPI 574 IRQ_TYPE_LEVEL_HIGH>,
				<GIC_SPI 575 IRQ_TYPE_LEVEL_HIGH>,
				<GIC_SPI 576 IRQ_TYPE_LEVEL_HIGH>,
				<GIC_SPI 577 IRQ_TYPE_LEVEL_HIGH>,
				<GIC_SPI 660 IRQ_TYPE_LEVEL_HIGH>,
				<GIC_SPI 662 IRQ_TYPE_LEVEL_HIGH>,
				<GIC_SPI 665 IRQ_TYPE_LEVEL_HIGH>,
				<GIC_SPI 666 IRQ_TYPE_LEVEL_HIGH>,
				<GIC_SPI 667 IRQ_TYPE_LEVEL_HIGH>,
				<GIC_SPI 669 IRQ_TYPE_LEVEL_HIGH>,
				<GIC_SPI 670 IRQ_TYPE_LEVEL_HIGH>,
				<GIC_SPI 700 IRQ_TYPE_LEVEL_HIGH>;

			power-domains = <&scmi15_pd 0>;
			power-domain-names = "power";
			status = "disabled";
		};

		pcie_smmu: iommu@9980000 {
			compatible = "arm,smmu-v3";
			reg = <0x0 0x9980000 0x0 0x20000>;
			interrupts = <GIC_SPI 898 IRQ_TYPE_EDGE_RISING>,
				<GIC_SPI 900 IRQ_TYPE_EDGE_RISING>,
				<GIC_SPI 902 IRQ_TYPE_EDGE_RISING>;
			interrupt-names = "eventq", "cmdq-sync", "gerror";
			dma-coherent;
			#iommu-cells = <1>;
			status = "disabled";
		};

		pdp_mbox0: mailbox@19980000 {
			compatible = "qcom,x1e80100-cpucp-mbox";
			reg = <0x0 0x19980000 0x0 0x300>,
				<0x0 0x17610000 0x0 0x4c08>;
			reg-names = "tx", "rx";
			qcom,rx-chans = <0x80b>;
			#mbox-cells = <1>;
			interrupts = <GIC_SPI 56 IRQ_TYPE_LEVEL_HIGH>;
		};

		pdp_mbox1: mailbox@1a980000 {
			compatible = "qcom,x1e80100-cpucp-mbox";
			reg = <0x0 0x1a980000 0x0 0x300>,
				<0x0 0x17610000 0x0 0x4c08>;
			reg-names = "tx", "rx";
			#mbox-cells = <1>;
			qcom,rx-chans = <0x1010>;
			interrupts = <GIC_SPI 56 IRQ_TYPE_LEVEL_HIGH>;
		};

		pdp_mbox2: mailbox@1b980000 {
			compatible = "qcom,x1e80100-cpucp-mbox";
			reg = <0x0 0x1b980000 0x0 0x300>,
				<0x0 0x17610000 0x0 0x4c08>;
			reg-names = "tx", "rx";
			#mbox-cells = <1>;
			qcom,rx-chans = <0x2020>;
			interrupts = <GIC_SPI 56 IRQ_TYPE_LEVEL_HIGH>;
		};

		cpucp_mbox: mailbox@18830000 {
			compatible = "qcom,x1e80100-cpucp-mbox";
			reg =   <0x0 0x18830000 0x0 0x300>,
				<0x0 0x17620000 0x0 0x4C08>;
			reg-names = "tx", "rx";
			#mbox-cells = <1>;
			interrupts = <GIC_SPI 50 IRQ_TYPE_LEVEL_HIGH>;
		};

		ipcc0: mailbox@9007000 {
			compatible = "qcom,seca-ipcc", "qcom,ipcc";
			reg = <0x0 0x9007000 0x0 0x1000>;
			interrupts = <GIC_SPI 247 IRQ_TYPE_LEVEL_HIGH>;
			interrupt-controller;
			#interrupt-cells = <3>;
			#mbox-cells = <2>;
		};

		ipcc1: mailbox@90c5000 {
			compatible = "qcom,seca-ipcc", "qcom,ipcc";
			reg = <0x0 0x90c5000 0x0 0x1000>;
			interrupts = <GIC_SPI 230 IRQ_TYPE_LEVEL_HIGH>;
			interrupt-controller;
			#interrupt-cells = <3>;
			#mbox-cells = <2>;
		};

		ipcc2: mailbox@9185000 {
			compatible = "qcom,seca-ipcc", "qcom,ipcc";
			reg = <0x0 0x9185000 0x0 0x1000>;
			interrupts = <GIC_SPI 231 IRQ_TYPE_LEVEL_HIGH>;
			interrupt-controller;
			#interrupt-cells = <3>;
			#mbox-cells = <2>;
		};

		tlmm: pinctrl@f000000 {
			compatible = "qcom,seca-tlmm";
			reg = <0x0 0x0f000000 0x0 0x1000000>;
			interrupts = <GIC_SPI 208 IRQ_TYPE_LEVEL_HIGH>;
			gpio-controller;
			#gpio-cells = <2>;
			interrupt-controller;
			#interrupt-cells = <2>;
			gpio-ranges = <&tlmm 0 0 181>;
		};

		memtimer: timer@17810000 {
			compatible = "arm,armv7-timer-mem";
			reg = <0x0 0x17810000 0x0 0x1000>;
			ranges = <0x0 0x0 0x0 0x20000000>;
			#address-cells = <1>;
			#size-cells = <1>;

			frame@17811000 {
				reg = <0x17811000 0x1000>,
				      <0x17812000 0x1000>;
				interrupts = <GIC_SPI 38 IRQ_TYPE_LEVEL_HIGH>,
					     <GIC_SPI 36 IRQ_TYPE_LEVEL_HIGH>;
				frame-number = <0>;
			};

			frame@17813000 {
				reg = <0x17813000 0x1000>;
				interrupts = <GIC_SPI 39 IRQ_TYPE_LEVEL_HIGH>;
				frame-number = <1>;
				status = "disabled";
			};

			frame@17815000 {
				reg = <0x17815000 0x1000>;
				interrupts = <GIC_SPI 40 IRQ_TYPE_LEVEL_HIGH>;
				frame-number = <2>;
				status = "disabled";
			};

			frame@17817000 {
				reg = <0x17817000 0x1000>;
				interrupts = <GIC_SPI 41 IRQ_TYPE_LEVEL_HIGH>;
				frame-number = <3>;
				status = "disabled";
			};

			frame@17819000 {
				reg = <0x17819000 0x1000>;
				interrupts = <GIC_SPI 42 IRQ_TYPE_LEVEL_HIGH>;
				frame-number = <4>;
				status = "disabled";
			};

			frame@1781b000 {
				reg = <0x1781b000 0x1000>;
				interrupts = <GIC_SPI 43 IRQ_TYPE_LEVEL_HIGH>;
				frame-number = <5>;
				status = "disabled";
			};

			frame@1781d000 {
				reg = <0x1781d000 0x1000>;
				interrupts = <GIC_SPI 44 IRQ_TYPE_LEVEL_HIGH>;
				frame-number = <6>;
				status = "disabled";
			};
		};

		arch_timer: timer {
			compatible = "arm,armv8-timer";
			interrupts = <GIC_PPI 13 (GIC_CPU_MASK_SIMPLE(8) | IRQ_TYPE_LEVEL_LOW)>,
				     <GIC_PPI 14 (GIC_CPU_MASK_SIMPLE(8) | IRQ_TYPE_LEVEL_LOW)>,
				     <GIC_PPI 11 (GIC_CPU_MASK_SIMPLE(8) | IRQ_TYPE_LEVEL_LOW)>,
				     <GIC_PPI 12 (GIC_CPU_MASK_SIMPLE(8) | IRQ_TYPE_LEVEL_LOW)>;
		};

		tcsr_mutex: hwlock@1f40000 {
			compatible = "qcom,tcsr-mutex";
			reg = <0x0 0x01f40000 0x0 0x20000>;
			#hwlock-cells = <1>;
		};

		watchdog@17826000 {
			compatible = "qcom,kpss-wdt";
			reg = <0x0 0x17826000 0x0 0x1000>;
			clocks = <&sleep_clk>;
			interrupts = <GIC_ESPI 848 IRQ_TYPE_EDGE_RISING>;
		};

		qupv3_id_2: geniqup@8c0000 {
			compatible = "qcom,sa8797p-geni-se-qup", "qcom,sa8255p-geni-se-qup";
			reg = <0x0 0x8c0000 0x0 0x2000>;
			#address-cells = <2>;
			#size-cells = <2>;
			ranges;
			status = "disabled";

			uart15: serial@884000 {
				compatible = "qcom,sa8797p-geni-debug-uart", "qcom,sa8255p-geni-debug-uart";
				reg = <0x0 0x884000 0x0 0x4000>;
				interrupts = <GIC_SPI 583 IRQ_TYPE_LEVEL_HIGH>;
				power-domains = <&scmi11_pd 15>, <&scmi11_dvfs 15>;
				power-domain-names = "power", "perf";
				status = "disabled";
			};
		};

		ufshc_mem: ufshc@1d44000 {
			compatible = "qcom,sa8255p-ufshc", "jedec,ufs-2.0";
			reg = <0 0x1d44000 0 0x3000>;
			reg-names = "ufs_mem";
			interrupts = <GIC_SPI 265 IRQ_TYPE_LEVEL_HIGH>;
			lanes-per-direction = <1>;
			#reset-cells = <1>;

			iommus = <&apps_smmu_0 0x14C0 0x0>;
			qcom,iommu-dma = "bypass";

			reset-gpios = <&tlmm 181 GPIO_ACTIVE_LOW>;

			status = "okay";
		};
	};
};
#include "seca-scmi.dtsi"
#include "seca-auto.dtsi"
